# apollo510 register map
Vendor: Ambiq Micro; Series: Apollo; File version: 1.0
CPU: CM55 r1p1, little endian, MPU, FPU, double-precision FPU, DSP, I-cache, D-cache, VTOR, ITCM, DTCM, 4 interrupt priority bits, 0 interrupts, 8 SAU regions
Registers are 32-bit, read-write, reset 0x0 unless marked. A register's access mark holds for its fields unless they carry their own. Offsets are from the block's base; [hi:lo] are bit positions; {n}, {i} and the like mark numbered series; 'fields as' and 'values as' point back to an identical list.

## CRYPTO (part 2 of 2) — Embedded security and cryptographic services
Base 0x400C0000
0x650 HASHH4 — H4 data. can only be written in the following HASH_CONTROL modes: SHA1 SHA224 SHA256 SHA384 SHA512
  [31:0] HASHH4 — 1) Write initial Hash value.
{0x640+4i} HASHH{i} (i=5..7) — H{i} data. can only be written in the following HASH_CONTROL modes: SHA224 SHA256 SHA384 SHA512
  [31:0] HASHH{i} — 1) Write initial Hash value.
0x660 HASHH8 — H8 data. can only be written in the following HASH_CONTROL modes: SHA384 SHA512
  [31:0] HASHH8 — 1) Write initial Hash value.
0x684 AUTOHWPADDING — HW padding automatically activated by engine. For the special case of ZERO bytes data vector this register should not be used! instead use HASH_PAD_CFG
  [0] EN — 0x1 - Enable Automatic HW padding (No need for SW intervention by writing PAD_CFG). Note: Not supported for 0 bytes ! Note: Disable this register when HASH op is done
0x688 HASHXORDIN — This register is always xored with the input to the hash engine,it should be 0 if xored is not reqiured .
  [31:0] HASHXORDATA — This register holds the value to be xor-ed with hash input data.
0x694 LOADINITSTATE — Indication to HASH that the following data is to be loaded into initial value registers in HASH(H0:H15) or IV to AES MAC
  [0] LOAD — Load data to initial state registers. digest_iv for hash_aes_mac. When done loading data this bit should be reset
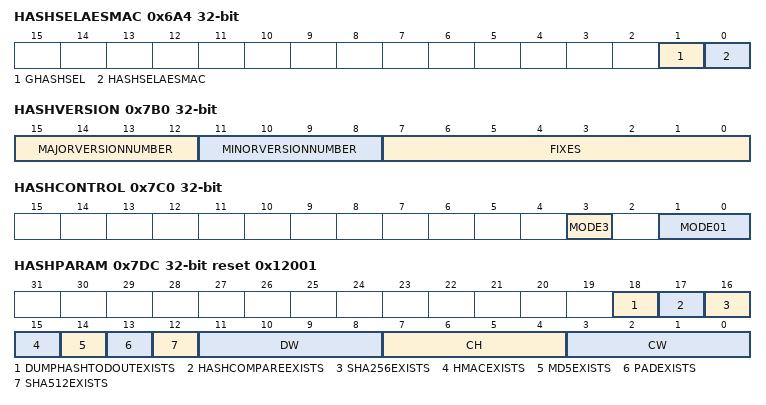
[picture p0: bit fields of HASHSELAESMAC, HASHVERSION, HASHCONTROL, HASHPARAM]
0x6A4 HASHSELAESMAC — select the AES MAC module rather than the hash module
  [1] GHASHSEL — GHASH select.
    0=HASH_MOD (select the hash module); 1=GHASH_MOD (select the ghash module)
  [0] HASHSELAESMAC — Hash or AES MAC module select.
    0=HASH_MOD (select the hash module); 1=MAC_MOD (select the AES mac module)
0x7B0 HASHVERSION
  [15:12] MAJORVERSIONNUMBER, [11:8] MINORVERSIONNUMBER, [7:0] FIXES
0x7C0 HASHCONTROL — Selects which HASH mode to run
  [3] MODE3 — bit 3 of the HASH mode field. The hash mode field possible values are:4b0000 - MD5 if present 0x0001 SHA 1 4b0010 - SHA-256 4b1010 - SHA-224
  [1:0] MODE01 — bits 1:0 of the HASH mode field. The hash mode field possible values are:
    0=MD5 (MD5 if present); 1=SHA_1; 2=SHA_256
0x7C4 HASHPADEN reset 0x1 — Enables the hash hw padding.
  [0] EN — 0x1 : Enable generation of padding by HW Pad block. 0x0 : Disable generation of padding by HW Pad block.
0x7C8 HASHPADCFG — This is a special register, affected by internal logic. Test result of this register is NA.
  [2] DOPAD — Enable Padding generation. must be reset upon completion of padding.
0x7CC HASHCURLEN0 — This register holds the length of current hash operation bit 31:0.
  [31:0] Length — Represent the current length of valid bits where digest need to be computed In Bytes.
0x7D0 HASHCURLEN1 — This register holds the length of current hash operation bit 63:32.
  fields as HASHCURLEN0
0x7DC HASHPARAM reset 0x12001
  [18] DUMPHASHTODOUTEXISTS — Indicate if HASH to dout is present in the design
  [17] HASHCOMPAREEXISTS — Indicate if COMPARE digest logic is present in the design
  [16] SHA256EXISTS — Indicate if SHA-256 is present in the design
  [15] HMACEXISTS — Indicate if HMAC logic is present in the design
  [14] MD5EXISTS — Indicate if MD5 is present in HW
  [13] PADEXISTS — Indicate if pad block is present in the design. 0 - pad function is not supported by hardware. 1 - pad function is supported by hardware.
  [12] SHA512EXISTS — Indicate if SHA-512 is present in the design. By default SHA-1 and SHA-256 are present. 0 - SHA-1 and SHA-256 are present only 1 - SHA-1 and all SHA-2 are present (SHA-256 SHA-512).
  [11:8] DW — Determine the granularity of word size. 0 - 32 bit word data. 1 - 64 bit word data.
  [7:4] CH — Indicate if Hi adders are present for each Hi value or 1 adder is shared for all Hi. 0 - One Hi value is updated at a time 1 - All Hi values are updated at the same time.
  [3:0] CW — Indicates the number of concurrent words the hash is using to compute signature. 1 - One concurrent w(t). 2 - Two concurrent w(t).
0x7E4 HASHAESSWRESET — Software reset of the AES.
  [0] HASHAESSWRESET — Hash receive reset internally.
0x7E8 HASHENDIANESS reset 0x1 — This register holds the HASH_ENDIANESS configuration.
  [0] ENDIAN — The default value is little-endian. The data and generation of padding can be swapped to be big-endian.
0x810 AESCLKENABLE — This is a special register, affected by internal logic. Test result of this register is NA.
  [0] EN — Enable the AES clock.
    1=CLK_E (the AES clock is enabled.); 0=CLK_D (the AES clock is disabled.)
0x818 HASHCLKENABLE — The HASH clock enable register. Note: This is a special register, affected by internal logic. Test result of this register is NA.
  [0] EN — Enable the hash clock.
    1=HASH_E (the HASH clock is enabled.); 0=HASH_D (the HASH clock is disabled.)
0x81C PKACLKENABLE — The PKA clock enable register. Note: This is a special register, affected by internal logic. Test result of this register is NA.
  [0] EN — Enable the PKA clock.
    1=PKA_E (the PKA clock is enabled.); 0=PKA_D (the PKA clock is disabled.)
0x820 DMACLKENABLE — DMA_CLK enable register. Note: This is a special register, affected by internal logic. Test result of this register is NA.
  [0] EN — Enable the DMA clock.
    1=DMA_E (the DMA clock is enabled.); 0=DMA_D (the DMA clock is disabled.)
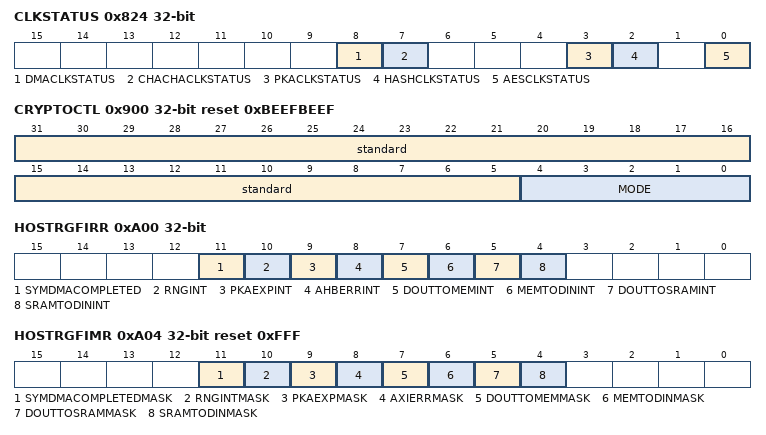
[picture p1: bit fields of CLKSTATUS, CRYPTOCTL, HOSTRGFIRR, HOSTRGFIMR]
0x824 CLKSTATUS — The CryptoCell clocks status register. Note: This is a special register, affected by internal logic. Test result of this register is NA.
  [8] DMACLKSTATUS — Status of DMA clock enable.
    values as DMACLKENABLE.EN
  [7] CHACHACLKSTATUS — Status of CHACHA clock enable.
    1=CHACHA_E (the CHACHA clock is enabled.); 0=CHACHA_D (the CHACHA clock is disabled.)
  [3] PKACLKSTATUS — Status of PKA clock enable.
    values as PKACLKENABLE.EN
  [2] HASHCLKSTATUS — Status of HASH clock clock enable.
    values as HASHCLKENABLE.EN
  [0] AESCLKSTATUS — Status of AES clock enable.
    values as AESCLKENABLE.EN
0x858 CHACHACLKENABLE — CHACHA _SALSA clock enable register. Note: This is a special register, affected by internal logic. Test result of this register is NA.
  [0] EN — Enable the CHACHA SALSA clock enable.
    1=CHACHA_E (the CHACHA SALSA clock is enabled.); 0=CHACHA_D (the CHACHA SALSA clock is disabled.)
0x900 CRYPTOCTL reset 0xBEEFBEEF — Defines the cryptographic flow.
  [31:5] standard — This field is reserved, do not modify.
  [4:0] MODE — Determines the active cryptographic engine:
    0=BYPASS; 1=AES; 2=AES_TO_HASH; 3=AES_AND_HASH; 4=DES; 5=DES_TO_HASH; 6=DES_AND_HASH; 7=HASH; 9=AES_MAC_AND_BYPASS; 10=AES_TO_HASH_AND_DOUT
0x910 CRYPTOBUSY — This register is set when the cryptographic core is busy.
  [0] CRYPTOBUSY — Crypto busy status.
    0=READY; 1=BUSY
0x91C HASHBUSY — This register is set when the Hash engine is busy.
  [0] HASHBUSY — Hash busy status.
    0=READY; 1=BUSY
0x930 CONTEXTID — A general RD_WR register. For Firmware use.
  [7:0] CONTEXTID
{0x960+4i} GHASHSUBKEY{i:02} (i=0..3) — Bits {32i+31}:{32i} of GHASH Key0 (used as the GHASH module key).
  [31:0] GHASHSUBKEY{i:02} — Bits {32i+31}:{32i} of GHASH Key0.
0x970 GHASHIV00 — Bits 31:0 of GHASH_IV0 register. GHASH IV0 is used as the GHASH IV (Initialization Value) register.
  [31:0] GHASHIV00 — Bits 31:0 of GHASH_IV0 register of the GHASH module. For the description of GHASH_IV0, see the GHASH_0_0 register description
0x974 GHASHIV01 — Bits 63:32 of GHASH_IV0 register. GHASH IV0 is used as the GHASH IV (Initialization Value) register.
  [31:0] GHASHIV01 — Bits 63:32 of GHASH_IV0 register of the GHASH module.
0x978 GHASHIV02 — Bits 95:64 of GHASH_IV0 register. GHASH IV0 is used as the GHASH IV (Initialization Value) register.
  [31:0] GHASHIV02 — Bits 95:64 of GHASH_IV0 register of the GHASH module.
0x97C GHASHIV03 — Bits 127:96 of GHASH_IV0 register.GHASH IV0 is used as the GHASH IV (Initialization Value) register.
  [31:0] GHASHIV03 — Bits 127:96 of GHASH_IV0 register of the GHASH module.
0x980 GHASHBUSY — The GHASH module GHASH_BUSY Register. This register is set when the GHASH core is active.
  [0] GHASHBUSY — GHASH_BUSY Register. This register is set when the GHASH core is active
0x984 GHASHINIT — Writing to this address sets the GHASH engine to be ready to a new GHASH operation.
  [0] GHASHINIT
0xA00 HOSTRGFIRR — The Interrupt Request register. Each bit of this register holds the interrupt status of a single interrupt source.
  [11] SYMDMACOMPLETED — The GPR interrupt status.
  [10] RNGINT — The RNG interrupt status.
  [9] PKAEXPINT — The PKA end of operation interrupt status.
  [8] AHBERRINT — The AXI error interrupt status.
  [7] DOUTTOMEMINT — The DOUT to memory DMA done interrupt status. This interrupt is asserted when all data was delivered to memory buffer from DOUT.
  [6] MEMTODININT — The memory to DIN DMA done interrupt status. This interrupt is asserted when all data was delivered to DIN buffer from memory.
  [5] DOUTTOSRAMINT — The DOUT to SRAM DMA done interrupt status. This interrupt is asserted when all data was delivered to SRAM buffer from DOUT.
  [4] SRAMTODININT — The SRAM to DIN DMA done interrupt status. This interrupt is asserted when all data was delivered to DIN buffer from SRAM.
0xA04 HOSTRGFIMR reset 0xFFF — The Interrupt Mask register. Each bit of this register holds the mask of a single interrupt source.
  [11] SYMDMACOMPLETEDMASK — The GPR interrupt mask.
  [10] RNGINTMASK — The RNG interrupt mask.
  [9] PKAEXPMASK — The PKA end of operation interrupt mask.
  [8] AXIERRMASK — The AXI error interrupt mask.
  [7] DOUTTOMEMMASK — The DOUT to memory DMA done interrupt mask.
  [6] MEMTODINMASK — The memory to DIN DMA done interrupt mask.
  [5] DOUTTOSRAMMASK — The DOUT to SRAM DMA done interrupt mask.
  [4] SRAMTODINMASK — The SRAM to DIN DMA done interrupt mask.
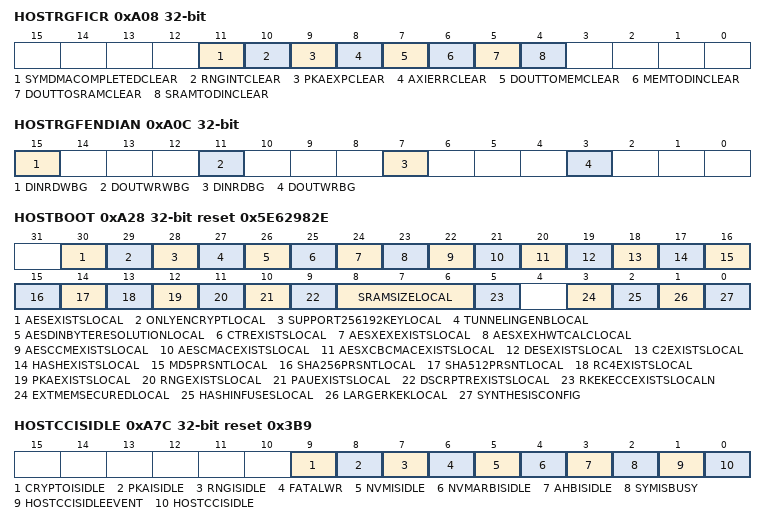
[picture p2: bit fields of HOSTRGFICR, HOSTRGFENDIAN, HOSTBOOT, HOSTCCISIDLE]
0xA08 HOSTRGFICR — Interrupt Clear Register.
  [11] SYMDMACOMPLETEDCLEAR — The GPR interrupt clear.
  [10] RNGINTCLEAR — The RNG interrupt clear.
  [9] PKAEXPCLEAR — The PKA end of operation interrupt clear.
  [8] AXIERRCLEAR — The AXI error interrupt clear.
  [7] DOUTTOMEMCLEAR — The DOUT to memory DMA done interrupt clear.
  [6] MEMTODINCLEAR — The memory to DIN DMA done interrupt clear.
  [5] DOUTTOSRAMCLEAR — The DOUT to SRAM DMA done interrupt clear.
  [4] SRAMTODINCLEAR — The SRAM to DIN DMA done interrupt clear.
0xA0C HOSTRGFENDIAN — This register defines the endianness of the Host-accessible registers. Note: This is a special register, affected by internal logic. Test result of this register is NA.
  [all] fields
    0=LE (little endian); 1=BE (big endian)
  [15] DINRDWBG — DIN write word endianness:
  [11] DOUTWRWBG — DOUT write word endianness:
  [7] DINRDBG — DIN write endianness:
  [3] DOUTWRBG — DOUT write endianness:
0xA24 HOSTRGFSIGNATURE reset 0x10E00000 — This register holds the CryptoCell product signature.
  [31:0] HOSTSIGNATURE — Identification 'signature': always returns a fixed value, used by Host driver to verify CryptoCell presence at this address.
0xA28 HOSTBOOT reset 0x5E62982E — This register holds the values of CryptoCells pre-synthesis flags
  [30] AESEXISTSLOCAL
  [29] ONLYENCRYPTLOCAL
  [28] SUPPORT256192KEYLOCAL
  [27] TUNNELINGENBLOCAL
  [26] AESDINBYTERESOLUTIONLOCAL
  [25] CTREXISTSLOCAL
  [24] AESXEXEXISTSLOCAL
  [23] AESXEXHWTCALCLOCAL
  [22] AESCCMEXISTSLOCAL
  [21] AESCMACEXISTSLOCAL
  [20] AESXCBCMACEXISTSLOCAL
  [19] DESEXISTSLOCAL
  [18] C2EXISTSLOCAL
  [17] HASHEXISTSLOCAL
  [16] MD5PRSNTLOCAL
  [15] SHA256PRSNTLOCAL
  [14] SHA512PRSNTLOCAL
  [13] RC4EXISTSLOCAL
  [12] PKAEXISTSLOCAL
  [11] RNGEXISTSLOCAL
  [10] PAUEXISTSLOCAL
  [9] DSCRPTREXISTSLOCAL
  [8:6] SRAMSIZELOCAL
  [5] RKEKECCEXISTSLOCALN
  [3] EXTMEMSECUREDLOCAL
  [2] HASHINFUSESLOCAL
  [1] LARGERKEKLOCAL
  [0] SYNTHESISCONFIG — POWER_GATING_EXISTS_LOCAL
0xA38 HOSTCRYPTOKEYSEL — AES hardware key select. Note: This is a special register, affected by internal logic. Test result of this register is NA.
  [2:0] SELCRYPTOKEY — Select the source of the HW key that is used by the AES engine:
    0=RKEK; 1=Krtl (the Krtl.); 2=KCP (the provision key KCP.); 3=KCE (the code encryption key KCE.); 4=KPICV (the KPICV, The ICV provisioning key .); 5=KCEICV (the code encryption key KCEICV Note: When 'kprtl_lock' is set - kprtl will be masked (trying to load it will load zeros to the AES key register. When 'kcertl_lock' is set - kcertl will be masked (trying to load it will load zeros to the AES key register. When scan_mode is asserted all the RTL keys (Krtll) will be masked.)
0xA78 HOSTCORECLKGATINGENABLE — This register enables the core clk gating by masking_enabling the cc_idle_state output signal.
  [0] HOSTCORECLKGATINGENABLE — Enable the core clk gating,
0xA7C HOSTCCISIDLE reset 0x3B9 — This register holds the idle indication of CC . Note: This is a special register, affected by internal logic. Test result of this register is NA.
  [9] CRYPTOISIDLE — crypto flow is done
  [8] PKAISIDLE
  [7] RNGISIDLE
  [6] FATALWR — fatal write
  [5] NVMISIDLE
  [4] NVMARBISIDLE — nvm arbiter is idle
  [3] AHBISIDLE — ahb stste machine is idle
  [2] SYMISBUSY — symetric flow is busy
  [1] HOSTCCISIDLEEVENT — The event that indicates that CC is idle.
  [0] HOSTCCISIDLE — Read if CC is idle.
0xA80 HOSTPOWERDOWN — This register start the power-down sequence. Note: This is a special register, affected by internal logic. Test result of this register is NA.
  [0] HOSTPOWERDOWN — Power down enable register.
0xA84 HOSTREMOVEGHASHENGINE — These inputs are to be statically tied to 0 or 1 by the customers. When such an input is set, the matching engines inputs are tied to zero and its outputs are disconnected, so that the engine will be entirely removed by Synthesis
  [0] HOSTREMOVEGHASHENGINE — Read the Remove_chacha_engine input
0xA88 HOSTREMOVECHACHAENGINE — These inputs are to be statically tied to 0 or 1 by the customers. When such an input is set, the matching engines inputs are tied to zero and its outputs are disconnected, so that the engine will be entirely removed by Synthesis
  [0] HOSTREMOVECHACHAENGINE — Read the Remove_ghash_engine input
0xB00 AHBMSINGLES — This register forces the ahb transactions to be always singles.
  [0] AHBSINGLES — Force ahb singles
0xB04 AHBMHPROT — This register holds the ahb prot value
  [3:0] AHBPROT — The ahb prot value
0xB08 AHBMHMASTLOCK — This register holds ahb hmastlock value
  [0] AHBHMASTLOCK — The hmastlock value.
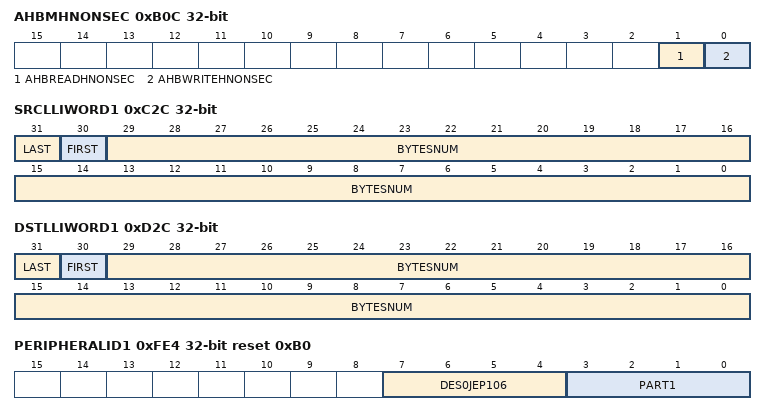
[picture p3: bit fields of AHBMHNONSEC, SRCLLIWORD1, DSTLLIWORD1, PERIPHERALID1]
0xB0C AHBMHNONSEC — This register holds ahb hnonsec value
  [1] AHBREADHNONSEC — The hnonsec value for read transaction.
  [0] AHBWRITEHNONSEC — The hnonsec value for write transaction.
0xC00 DINBUFFER reset 0x8770 — This address can be used by the CPU to write data directly to the DIN buffer to be sent to engines.
  [31:0] DINBUFFERDATA — This register is mapped into 8 addresses in order to enable a CPU burst.
0xC20 DINMEMDMABUSY — Indicates whether memory (AXI) source DMA (DIN) is busy.
  [0] DINMEMDMABUSY — DIN memory DMA busy
    1=busy (DMA busy); 0=not (DMA not busy)
0xC28 SRCLLIWORD0 — This register is used in direct LLI mode - holds the location of the data source in the memory (AXI).
  [31:0] SRCLLIWORD0 — Source address within memory.
0xC2C SRCLLIWORD1 — This register is used in direct LLI mode - holds the number of bytes to be read from the memory (AXI). Writing to this register triggers the DMA. Note: This is a special register, affected by internal logic. Test result of this register is NA.
  [31] LAST — 0x1 - Indicates the last LLI entry
  [30] FIRST — 0x1 - Indicates the first LLI entry
  [29:0] BYTESNUM — Total number of bytes to read using DMA in this entry
0xC30 SRAMSRCADDR — Location of data (start address) to be read from SRAM. Note: This is a special register, affected by internal logic. Test result of this register is NA.
  [31:0] SRAMSOURCE — SRAM source base address of data
0xC34 DINSRAMBYTESLEN — This register holds the size of the data (in bytes) to be read from the SRAM. Note: This is a special register, affected by internal logic. Test result of this register is NA.
  [31:0] BYTESLEN — Size of data to read from SRAM (bytes). This is the trigger to the SRAM SRC DMA.
0xC38 DINSRAMDMABUSY — This register holds the status of the SRAM DMA DIN.
  [0] BUSY — DIN SRAM DMA busy:
    1=BUSY; 0=NOT_BUSY
0xC3C DINSRAMENDIANNESS — This register defines the endianness of the DIN interface to SRAM.
  [0] SRAMDINENDIANNESS — Defines the endianness of DIN interface to SRAM:
    1=BE (big-endianness); 0=LE (little endianness)
0xC48 DINCPUDATASIZE — This register hold the number of bytes to be transmited using external DMA. Note: This is a special register, affected by internal logic. Test result of this register is NA.
  [15:0] CPUDINSIZE — When using external DMA, the size of transmited data in bytes should be written to this register.
0xC50 FIFOINEMPTY reset 0x1 — DIN FIFO empty indication
  [0] EMPTY — 0x1 - FIFO empty
0xC58 DINFIFORSTPNTR reset 0x1 — Writing to this register resets the DIN_FIFO pointers.
  [0] RST — Writing any value to this address resets the DIN_FIFO pointers.
0xD20 DOUTMEMDMABUSY — DOUT memory DMA busy - Indicates that memory (AXI) destination DMA (DOUT) is busy,
  [0] DOUTMEMDMABUSY — DOUT memory DMA busy:
    1=BUSY; 0=NOT_BUSY
0xD28 DSTLLIWORD0 — This register is used in direct LLI mode - holds the location of the data destination in the memory (AXI)
  [31:0] DSTLLIWORD0 — Destination address within memory
0xD2C DSTLLIWORD1 — This register is used in direct LLI mode - holds the number of bytes to be written to the memory (AXI). Note: This is a special register, affected by internal logic. Test result of this register is NA.
  [31] LAST — 0x1 - Indicates the last LLI entry
  [30] FIRST — 0x1 - Indicates the first LLI entry
  [29:0] BYTESNUM — Total byte number to be written by DMA in this entry
0xD30 SRAMDESTADDR — Location of result to be sent to in SRAM. Note: This is a special register, affected by internal logic. Test result of this register is NA.
  [31:0] SRAMDEST — SRAM destination base address for data.
0xD34 DOUTSRAMBYTESLEN — This register holds the size of the data (in bytes) to be written to the SRAM. Note: This is a special register, affected by internal logic. Test result of this register is NA.
  [31:0] BYTESLEN — Size of data to write to SRAM (bytes). This is the trigger to the SRAM DST DMA.
0xD38 DOUTSRAMDMABUSY — This register holds the status of the SRAM DMA DOUT.
  [0] BUSY — DOUT SRAM DMA busy status.
    0=DATA_SRAM (all data was written to SRAM.); 1=DMA_BUSY (DOUT SRAM DMA busy.)
0xD3C DOUTSRAMENDIANNESS — This register defines the endianness of the DOUT interface from SRAM.
  [0] DOUTSRAMENDIANNESS — Defines the endianness of DOUT interface from SRAM:
    1=BE (big-endianness); 0=LE (little endianness)
0xD44 READALIGNLAST — Indication that the next read from the CPU is the last one. This is needed only when the data size is NOT modulo 4 (e.g. HASH padding).
  [0] LAST — 0x1 - Flush the read aligner content (used for reading the last data).
0xD50 DOUTFIFOEMPTY reset 0x1
  [0] DOUTFIFOEMPTY — DOUT FIFO empty status.
    0=FIFO_NE (DOUT FIFO is not empty); 1=FIFO_EDOUT (FIFO is empty)
0xF00 SRAMDATA — READ WRITE DATA FROM SRAM. Note: This is a special register, affected by internal logic. Test result of this register is NA.
  [31:0] SRAMDATA — 32 bit write or read from SRAM: read - triggers the SRAM read DMA address automatically incremented write - triggers the SRAM write DMA address automatically incremented
0xF04 SRAMADDR — first address given to SRAM DMA for read_write transactions from SRAM
  [14:0] SRAMADDR — SRAM starting address
0xF08 SRAMDATAREADY reset 0x1 — The SRAM content is ready for read in SRAM_DATA.
  [0] SRAMREADY — SRAM content is ready for read in SRAM_DATA.
0xFD0 PERIPHERALID4 reset 0x4 — Peripheral ID 4 (PID4).
  [3:0] DES2JEP106 — for ARM products.
0xFE0 PERIPHERALID0 reset 0xC0 — Peripheral ID 0 (PID0).
  [7:0] PART0 — Identification register part number, bits[7:0]
0xFE4 PERIPHERALID1 reset 0xB0 — Peripheral ID 1 (PID1).
  [7:4] DES0JEP106 — for ARM products.
  [3:0] PART1 — Identification register part number, bits[11:8]
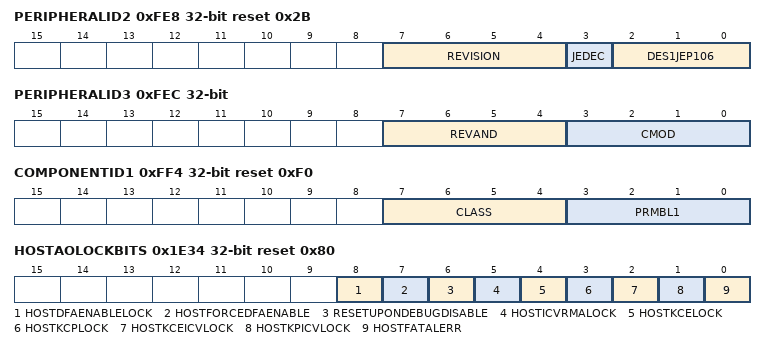
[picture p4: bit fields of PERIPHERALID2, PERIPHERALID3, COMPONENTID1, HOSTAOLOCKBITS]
0xFE8 PERIPHERALID2 reset 0x2B — Peripheral ID 2 (PID2).
  [7:4] REVISION — starts at zero and increments for every new IP release.
  [3] JEDEC — constant 0x1. Indicates that a JEDEC assigned value is used.
  [2:0] DES1JEP106 — for ARM products.
0xFEC PERIPHERALID3 — Peripheral ID 3 (PID3).
  [7:4] REVAND — starts at zero for every Revision, and increments if metal fixes are applied between 2 IP releases.
  [3:0] CMOD — Customer Modified, normally zero, but if a partner applies any changes themselves, they must change this value.
0xFF0 COMPONENTID0 reset 0xD
  [7:0] PRMBL0 — constant 0xD
0xFF4 COMPONENTID1 reset 0xF0
  [7:4] CLASS — component type 0 0xF for Cryptocell
  [3:0] PRMBL1 — constant 0x0
0xFF8 COMPONENTID2 reset 0x5
  [7:0] PRMBL2 — constant 0x5
0xFFC COMPONENTID3 reset 0xB1
  [7:0] PRMBL3 — constant 0xB1
{0x1E00+4i} HOSTDCUEN{i} reset 0xFFFFFFFF (i=0..2) — The DCU [{32i+31}:{32i}] enable register. Note: This is a special register, affected by internal logic. Test result of this register is NA.
  [31:0] HOSTDCUEN{i} — Debug Control Unit (DCU) Enable bits.
0x1E0C HOSTDCUEN3 reset 0xFFFFFFFF — The DCU [1271:96] enable register. Note: This is a special register, affected by internal logic. Test result of this register is NA.
  [31:0] HOSTDCUEN3 — Debug Control Unit (DCU) Enable bits.
{0x1E10+4i} HOSTDCULOCK{i} (i=0..3) — The DCU lock register. Note: This is a special register, affected by internal logic. Test result of this register is NA.
  [31:0] HOSTDCULOCK{i} — DCU_lock [{32i+31}:{32i}] register (a dedicated lock register per DCU bit).
0x1E20 AOICVDCURESTRICTIONMASK0 reset 0xFFFFFFFF — The DCU lock register.
  [31:0] AOICVDCURESTRICTIONMASK0 — AO_ICV_DCU_RESTRICTION_MASK [31:0] parameter, that will be a customer modifiable.
0x1E24 AOICVDCURESTRICTIONMASK1 reset 0xFFFFFFFF — The 'ICV_DCU_restriction_mask' parameter is read by FW during the secure debug verification to prevent OEM from setting specific DCUs that protect ICV secrets
  [31:0] AOICVDCURESTRICTIONMASK1 — AO_ICV_DCU_RESTRICTION_MASK [63:32] parameter, that will be a customer modifiable.
0x1E28 AOICVDCURESTRICTIONMASK2 — The 'ICV_DCU_restriction_mask' parameter is read by FW during the secure debug verification to prevent OEM from setting specific DCUs that protect ICV secrets
  [31:0] AOICVDCURESTRICTIONMASK2 — AO_ICV_DCU_RESTRICTION_MASK [95:64] parameter, that will be a customer modifiable.
0x1E2C AOICVDCURESTRICTIONMASK3 — The 'ICV_DCU_restriction_mask' parameter is read by FW during the secure debug verification to prevent OEM from setting specific DCUs that protect ICV secrets
  [31:0] AOICVDCURESTRICTIONMASK3 — AO_ICV_DCU_RESTRICTION_MASK [127:96] parameter, that will be a customer modifiable.
0x1E30 AOCCSECDEBUGRESET — The reset-upon-debug indication
  [0] AOCCSECDEBUGRESET — For resets Cerberus, and prevents loading the HW keys after that reset
0x1E34 HOSTAOLOCKBITS reset 0x80 — These masks will define, per LCS, which DCU bits will be tied to zero, even if the Host tries to set them. Note: This is a special register, affected by internal logic. Test result of this register is NA.
  [8] HOSTDFAENABLELOCK — When this FW control is set, the DFA_ENABLE register cant be written until the next POR. The DFA_ENABLE_LOCK register is set-once (per POR).
  [7] HOSTFORCEDFAENABLE — When this FW controlled register is set, the AES DFA countermeasures are enabled_disabled (regardless of the AES_DFA_IS_ON register value).
  [6] RESETUPONDEBUGDISABLE — The RESET_UPON_DEBUG_DISABLE register is set-once (per POR).
  [5] HOSTICVRMALOCK — The ICV_RMA_LOCK register is set-once (per POR).
  [4] HOSTKCELOCK — When this FW controlled register is set, the Kce HW key is masked (to zero).
  [3] HOSTKCPLOCK — When this FW controlled register is set, the Kcp HW key is masked (to zero).
  [2] HOSTKCEICVLOCK — When this FW controlled register is set, the Kceicv HW key is masked (to zero).
  [1] HOSTKPICVLOCK — When this FW controlled register is set, the Kpicv HW key is masked (to zero).
  [0] HOSTFATALERR — When the 'FATAL_ERROR' register is asserted - HW keys will not be copied from OTP
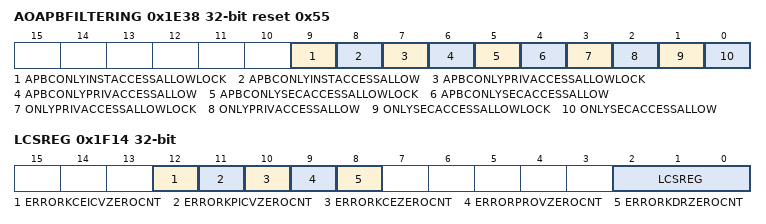
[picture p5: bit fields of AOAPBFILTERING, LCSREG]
0x1E38 AOAPBFILTERING reset 0x55 — This register holds the AO_APB_FILTERING data. Note: This is a special register, affected by internal logic. Test result of this register is NA.
  [9] APBCONLYINSTACCESSALLOWLOCK — when this FW controlled register is set, the APBC_ONLY_INST_ACCESS_ALLOWED register cant be modified (until the next POR)
  [8] APBCONLYINSTACCESSALLOW — when this FW controlled register is set, the APB-C slave accepts only instruction accesses
  [7] APBCONLYPRIVACCESSALLOWLOCK — when this FW controlled register is set, the APBC_ONLY_PRIV_ACCESS_ALLOWED register cant be modified (until the next POR)
  [6] APBCONLYPRIVACCESSALLOW — when this FW controlled register is set, the APB-C slave accepts only privileged accesses
  [5] APBCONLYSECACCESSALLOWLOCK — when this FW controlled register is set, the APBC_ONLY_SEC_ACCESS_ALLOWED register cant be modified (until the next POR).
  [4] APBCONLYSECACCESSALLOW — when this FW controlled register is set, the APB-C slave accepts only secure accesses
  [3] ONLYPRIVACCESSALLOWLOCK — when this FW controlled register is set, the APBC_ONLY_PRIV_ACCESS_ALLOWED register cant be modified (until the next POR)
  [2] ONLYPRIVACCESSALLOW — when this FW controlled register is set, the APB slave accepts only privileged accesses
  [1] ONLYSECACCESSALLOWLOCK — when this FW controlled register is set, the ONLY_SEC_ACCESS_ALLOWED register cant be modified (until the next POR).
  [0] ONLYSECACCESSALLOW — when this FW controlled register is set, the APB slave accepts only secure accesses
0x1E3C AOCCGPPC — holds the AO_CC_GPPC value from AONote: This is a special register, affected by internal logic. Test result of this register is NA.
  [7:0] AOCCGPPC — The AO_CC_GPPC value
0x1E40 HOSTRGFCCSWRST — Writing to this register generates a general reset to CryptoCell. This reset takes about 4 core clock cycles.Note: This is a special register, affected by internal logic. Test result of this register is NA.
  [0] HOSTRGFCCSWRST — Writing 1 to this field generates a general reset to CryptoCell.
0x1F04 AIBFUSEPROGCOMPLETED — This register reflects the fuse_aib_prog_completed input, which indicates that the fuse programming was completed.Note: This is a special register, affected by internal logic. Test result of this register is NA.
  [0] AIBFUSEPROGCOMPLETED — Indicates if the fuse programming operation has been completed.
0x1F08 NVMDEBUGSTATUS reset 0xE — AIB debug status register. Note: This is a special register, affected by internal logic. Test result of this register is NA.
  [3:1] NVMSM — Main nvm fsm
    0=IDLE (IDLE NVMSM); 1=READ_DUMMY (READ_DUMMY NVMSM); 2=READ_MAN_FLAG (READ_MAN_FLAG NVMSM); 3=READ_OEM_FLAG (READ_OEM_FLAG NVMSM); 4=READ_GPPC (READ_GPPC NVMSM); 5=DECODE (DECODE NVMSM); 6=OTP_LCS_VALID (OTP_LCS_VALID NVMSM); 7=LCS_IS_VALID (LCS_IS_VALID NVMSM)
0x1F0C LCSISVALID reset 0x1 — Indicates that the LCS register holds a valid value.Note: This is a special register, affected by internal logic. Test result of this register is NA.
  [0] LCSISVALIDREG — Indicates whether LCS is valid.
0x1F10 NVMISIDLE reset 0x1 — Indicates that the LCS register holds a valid value.Note: This is a special register, affected by internal logic. Test result of this register is NA.
  [0] NVMISIDLEREG — Indicates whether the NVM manager finishes its operation, calculates the LCS, reads the HW keys, compares the number of zeros and clears the keys
0x1F14 LCSREG — The lifecycle state register. Note: This is a special register, affected by internal logic. Test result of this register is NA.
  [12] ERRORKCEICVZEROCNT — Indication that the number of zeroes in the loaded KCEICV is not equal to the value set in the manufacture flag.
  [11] ERRORKPICVZEROCNT — Indication that the number of zeroes in the loaded KPICV is not equal to the value set in the manufacture flag.
  [10] ERRORKCEZEROCNT — Indication that the number of zeroes in the loaded KCE is not equal to the value set in the OEM flag.
  [9] ERRORPROVZEROCNT — Indication that the number of zeroes in the loaded KCP is not equal to the value set in the OEM flag.
  [8] ERRORKDRZEROCNT — Indication that the number of zeroes in the loaded KDR is not equal to the value set in the manufacture flag.
  [2:0] LCSREG — Indicates the LCS (Lifecycle State) value.
    0=CM (CM lifecycle state); 1=DM (DM lifecycle state); 5=SE (SE lifecycle state); 7=RMA (RMA lifecycle state)
0x1F18 HOSTSHADOWKDRREG — This register interface is used to update the RKEK(KDR) registers when the device is in CM or DM mode , it is Write-once (per warm boot) in RMA LCS, The RKEK is updated by shifting .
  [0] HOSTSHADOWKDRREG — This field is used to update the KDR registers when the device is in CM , DM or RMA mode, The KDR is updated by shifting .
0x1F1C HOSTSHADOWKCPREG — This register interface is used to update the KCP registers when the device is in CM or DM mode, The KCP is updated by shifting
  [0] HOSTSHADOWKCPREG — This field is used to update the KCP registers when the device is in CM or DM mode, The KCP is updated by shifting
0x1F20 HOSTSHADOWKCEREG — This register interface is used to update the KCE registers when the device is in CM or DM mode, The KCE is updated by shifting
  [0] HOSTSHADOWKCEREG — This field is used to update the KCE registers when the device is in CM or DM mode, The KCE is updated by shifting
0x1F24 HOSTSHADOWKPICVREG — This register interface is used to update the KPICV registers when the device is in CM or DM mode, The KPICV is updated by shifting
  [0] HOSTSHADOWKPICVREG — This field is used to update the KPICV registers when the device is in CM or DM mode, The KPICV is updated by shifting
0x1F28 HOSTSHADOWKCEICVREG — This register interface is used to update the KCEICV registers when the device is in CM or DM mode, The KCEICV is updated by shifting
  [0] HOSTSHADOWKCEICVREG — This field is used to update the KCEICV registers when the device is in CM or DM mode, The KCEICV is updated by shifting
0x1F2C OTPADDRWIDTHDEF reset 0xB — OTP_ADDR_WIDTH parameter, that will define the integrated OTP address width (address in words). The supported sizes are 6 (for 2 Kbits),7,8,9,11 (for 64 Kbits). The default value in the provided RTL will be 6.Note: This is a special register, affected by internal logic. Test result of this register is NA.
  [3:0] OTPADDRWIDTHDEF — Holds the OTP_ADDR_WIDTH_DEF value.
